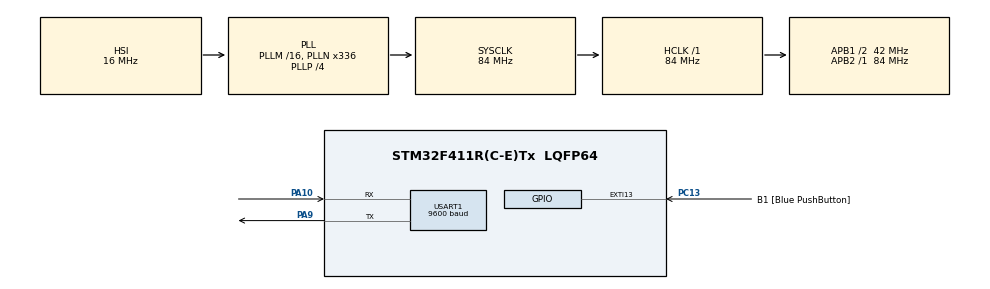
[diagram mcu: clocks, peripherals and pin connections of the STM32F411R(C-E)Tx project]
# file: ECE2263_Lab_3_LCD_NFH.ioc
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Mcu.Family=STM32F4
Mcu.Name=STM32F411R(C-E)Tx
Mcu.Package=LQFP64
NVIC.EXTI15_10_IRQn=true\:0\:0\:false\:false\:true\:true\:true
NVIC.PriorityGroup=NVIC_PRIORITYGROUP_0
PA10.Mode=Asynchronous
PA10.Signal=USART1_RX
PA13.GPIO_Label=TMS
PA13.Mode=Serial_Wire
PA13.Signal=SYS_JTMS-SWDIO
PA14.GPIO_Label=TCK
PA14.Mode=Serial_Wire
PA14.Signal=SYS_JTCK-SWCLK
PA2.GPIO_Label=USART_TX
PA2.GPIO_ModeDefaultPP=GPIO_MODE_AF_OD
PA2.GPIO_PuPd=GPIO_NOPULL
PA2.GPIO_Speed=GPIO_SPEED_FREQ_HIGH
PA2.Signal=USART2_TX
PA3.GPIO_Label=USART_RX
PA3.Signal=USART2_RX
PA9.Mode=Asynchronous
PA9.Signal=USART1_TX
PB3.GPIO_Label=SWO
PB3.Signal=SYS_JTDO-SWO
PC13-ANTI_TAMP.GPIO_Label=B1 [Blue PushButton]
PC13-ANTI_TAMP.GPIO_ModeDefaultEXTI=GPIO_MODE_IT_FALLING
PC13-ANTI_TAMP.Signal=GPXTI13
PC14-OSC32_IN.Signal=RCC_OSC32_IN
PC15-OSC32_OUT.Signal=RCC_OSC32_OUT
PH0\ -\ OSC_IN.Signal=RCC_OSC_IN
PH1\ -\ OSC_OUT.Signal=RCC_OSC_OUT
ProjectManager.HeapSize=0x200
ProjectManager.StackSize=0x400
ProjectManager.TargetToolchain=STM32CubeIDE
RCC.48MHZClocksFreq_Value=84000000
RCC.AHBFreq_Value=84000000
RCC.APB1CLKDivider=RCC_HCLK_DIV2
RCC.APB1Freq_Value=42000000
RCC.APB1TimFreq_Value=84000000
RCC.APB2Freq_Value=84000000
RCC.APB2TimFreq_Value=84000000
RCC.CortexFreq_Value=84000000
RCC.FLatency-AdvancedSettings=FLASH_LATENCY_2
RCC.HCLKFreq_Value=84000000
RCC.HSE_VALUE=8000000
RCC.HSI_VALUE=16000000
RCC.PLLN=336
RCC.PLLP=RCC_PLLP_DIV4
RCC.PWR_Regulator_Voltage_Scale=PWR_REGULATOR_VOLTAGE_SCALE2
RCC.SYSCLKFreq_VALUE=84000000
RCC.SYSCLKSource=RCC_SYSCLKSOURCE_PLLCLK
RCC.VCOOutputFreq_Value=336000000
USART1.BaudRate=9600
USART1.VirtualMode=VM_ASYNC
board=NUCLEO-F411RE

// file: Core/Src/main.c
/* USER CODE BEGIN Header */
/**
  ******************************************************************************
  * @file           : main.c
  * @brief          : Main program body
  ******************************************************************************
  * @attention
  *
  * <h2><center>&copy; Copyright (c) 2020 STMicroelectronics.
  * All rights reserved.</center></h2>
  *
  * This software component is licensed by ST under BSD 3-Clause license,
  * the "License"; You may not use this file except in compliance with the
  * License. You may obtain a copy of the License at:
  *                        opensource.org/licenses/BSD-3-Clause
  *
  ******************************************************************************
  */
/* USER CODE END Header */

#include "main.h"

/* USER CODE BEGIN Includes */
#include "string.h"
#include "stdlib.h"
#include "stdbool.h"
#include "stdio.h"
#include "memory.h"
#include "stdint.h"
#include "stm32f4xx_hal.h"
#include "stm32f4xx_hal_exti.h"
#include "stm32f4xx_hal_flash_ex.h"
#include "stm32f4xx_hal_flash.h"
#include "stm32f4xx_hal_gpio.h"
/* USER CODE END Includes */

UART_HandleTypeDef huart1;

/* USER CODE BEGIN PV */
volatile uint8_t screenState;
/* USER CODE END PV */

void SystemClock_Config(void);
static void MX_GPIO_Init(void);
static void MX_USART1_UART_Init(void);
/* USER CODE BEGIN PFP */
void screenClear(void);
/* USER CODE END PFP */

int main(void)
{

  /* MCU Configuration--------------------------------------------------------*/

  /* Reset of all peripherals, Initializes the Flash interface and the Systick. */
  HAL_Init();

  /* Configure the system clock */
  SystemClock_Config();

  /* Initialize all configured peripherals */
  MX_GPIO_Init();
  MX_USART1_UART_Init();
  /* USER CODE BEGIN 2 */
  char Message[]="Counter: ";
  char newLine[]="\r\n";

  uint8_t clearInstruction[]={0x7C, 0x2D};

  HAL_UART_Transmit(&huart1, (uint8_t *) clearInstruction, sizeof(clearInstruction), HAL_MAX_DELAY);

  	 uint8_t inc = 0;

  /* USER CODE END 2 */

  /* Infinite loop */
  /* USER CODE BEGIN WHILE */
  while (1)
  {
	char print[3];
	itoa(inc,print,10);

	HAL_UART_Transmit(&huart1, (uint8_t *) Message, strlen(Message), HAL_MAX_DELAY);
	HAL_UART_Transmit(&huart1, (uint8_t *) print, strlen(print), HAL_MAX_DELAY);
	HAL_UART_Transmit(&huart1, (uint8_t *) newLine, strlen(newLine), HAL_MAX_DELAY);
	HAL_Delay(1000);

	inc++;
	if(screenState == 1){
		screenClear();
		screenState = 0;
	}
    /* USER CODE END WHILE */

  }
}

void SystemClock_Config(void)
{
  RCC_OscInitTypeDef RCC_OscInitStruct = {0};
  RCC_ClkInitTypeDef RCC_ClkInitStruct = {0};

  /** Configure the main internal regulator output voltage
  */
  __HAL_RCC_PWR_CLK_ENABLE();
  __HAL_PWR_VOLTAGESCALING_CONFIG(PWR_REGULATOR_VOLTAGE_SCALE2);
  /** Initializes the CPU, AHB and APB busses clocks
  */
  RCC_OscInitStruct.OscillatorType = RCC_OSCILLATORTYPE_HSI;
  RCC_OscInitStruct.HSIState = RCC_HSI_ON;
  RCC_OscInitStruct.HSICalibrationValue = RCC_HSICALIBRATION_DEFAULT;
  RCC_OscInitStruct.PLL.PLLState = RCC_PLL_ON;
  RCC_OscInitStruct.PLL.PLLSource = RCC_PLLSOURCE_HSI;
  RCC_OscInitStruct.PLL.PLLM = 16;
  RCC_OscInitStruct.PLL.PLLN = 336;
  RCC_OscInitStruct.PLL.PLLP = RCC_PLLP_DIV4;
  RCC_OscInitStruct.PLL.PLLQ = 4;
  if (HAL_RCC_OscConfig(&RCC_OscInitStruct) != HAL_OK)
  {
    Error_Handler();
  }
  /** Initializes the CPU, AHB and APB busses clocks
  */
  RCC_ClkInitStruct.ClockType = RCC_CLOCKTYPE_HCLK|RCC_CLOCKTYPE_SYSCLK
                              |RCC_CLOCKTYPE_PCLK1|RCC_CLOCKTYPE_PCLK2;
  RCC_ClkInitStruct.SYSCLKSource = RCC_SYSCLKSOURCE_PLLCLK;
  RCC_ClkInitStruct.AHBCLKDivider = RCC_SYSCLK_DIV1;
  RCC_ClkInitStruct.APB1CLKDivider = RCC_HCLK_DIV2;
  RCC_ClkInitStruct.APB2CLKDivider = RCC_HCLK_DIV1;

  if (HAL_RCC_ClockConfig(&RCC_ClkInitStruct, FLASH_LATENCY_2) != HAL_OK)
  {
    Error_Handler();
  }
}

static void MX_USART1_UART_Init(void)
{

  huart1.Instance = USART1;
  huart1.Init.BaudRate = 9600;
  huart1.Init.WordLength = UART_WORDLENGTH_8B;
  huart1.Init.StopBits = UART_STOPBITS_1;
  huart1.Init.Parity = UART_PARITY_NONE;
  huart1.Init.Mode = UART_MODE_TX_RX;
  huart1.Init.HwFlowCtl = UART_HWCONTROL_NONE;
  huart1.Init.OverSampling = UART_OVERSAMPLING_16;
  if (HAL_UART_Init(&huart1) != HAL_OK)
  {
    Error_Handler();
  }

}

static void MX_GPIO_Init(void)
{
  GPIO_InitTypeDef GPIO_InitStruct = {0};

  /* GPIO Ports Clock Enable */
  __HAL_RCC_GPIOC_CLK_ENABLE();
  __HAL_RCC_GPIOH_CLK_ENABLE();
  __HAL_RCC_GPIOA_CLK_ENABLE();
  __HAL_RCC_GPIOB_CLK_ENABLE();

  /*Configure GPIO pin : B1_Pin */
  GPIO_InitStruct.Pin = B1_Pin;
  GPIO_InitStruct.Mode = GPIO_MODE_IT_FALLING;
  GPIO_InitStruct.Pull = GPIO_NOPULL;
  HAL_GPIO_Init(B1_GPIO_Port, &GPIO_InitStruct);

  /*Configure GPIO pin : USART_TX_Pin */
  GPIO_InitStruct.Pin = USART_TX_Pin;
  GPIO_InitStruct.Mode = GPIO_MODE_AF_OD;
  GPIO_InitStruct.Pull = GPIO_NOPULL;
  GPIO_InitStruct.Speed = GPIO_SPEED_FREQ_HIGH;
  GPIO_InitStruct.Alternate = GPIO_AF7_USART2;
  HAL_GPIO_Init(USART_TX_GPIO_Port, &GPIO_InitStruct);

  /*Configure GPIO pin : USART_RX_Pin */
  GPIO_InitStruct.Pin = USART_RX_Pin;
  GPIO_InitStruct.Mode = GPIO_MODE_AF_PP;
  GPIO_InitStruct.Pull = GPIO_NOPULL;
  GPIO_InitStruct.Speed = GPIO_SPEED_FREQ_VERY_HIGH;
  GPIO_InitStruct.Alternate = GPIO_AF7_USART2;
  HAL_GPIO_Init(USART_RX_GPIO_Port, &GPIO_InitStruct);

  /* EXTI interrupt init*/
  HAL_NVIC_SetPriority(EXTI15_10_IRQn, 0, 0);
  HAL_NVIC_EnableIRQ(EXTI15_10_IRQn);

}

/* USER CODE BEGIN 4 */
void screenClear(void){
	uint8_t clearInstruction[]={0x7C, 0x2D};
	HAL_UART_Transmit(&huart1, (uint8_t *) clearInstruction, sizeof(clearInstruction), HAL_MAX_DELAY);

}
/* USER CODE END 4 */

void Error_Handler(void)
{
}

/************************ (C) COPYRIGHT STMicroelectronics *****END OF FILE****/
